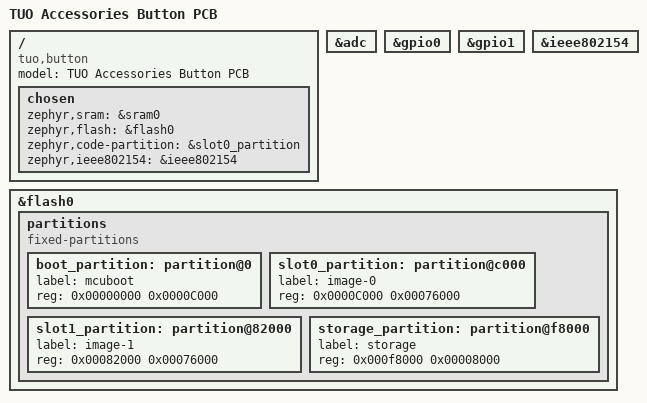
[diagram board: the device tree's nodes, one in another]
/dts-v1/;
#include <nordic/nrf52840_qiaa.dtsi>

/ {
  model = "TUO Accessories Button PCB";
  compatible = "tuo,button";

  chosen {
    zephyr,sram = &sram0;
    zephyr,flash = &flash0;
    zephyr,code-partition = &slot0_partition;
    zephyr,ieee802154 = &ieee802154;
  };
};

&adc {
  status = "okay";
};

&gpio0 {
  status = "okay";
};

&gpio1 {
  status = "okay";
};

&ieee802154 {
  status = "okay";
};

&flash0 {
    partitions {
        compatible = "fixed-partitions";
        #address-cells = <1>;
        #size-cells = <1>;

        boot_partition: partition@0 {
          label = "mcuboot";
          reg = <0x00000000 0x0000C000>;
        };
        slot0_partition: partition@c000 {
          label = "image-0";
          reg = <0x0000C000 0x00076000>;
        };
        slot1_partition: partition@82000 {
          label = "image-1";
          reg = <0x00082000 0x00076000>;
        };
        storage_partition: partition@f8000 {
          label = "storage";
          reg = <0x000f8000 0x00008000>;
        };
    };
};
